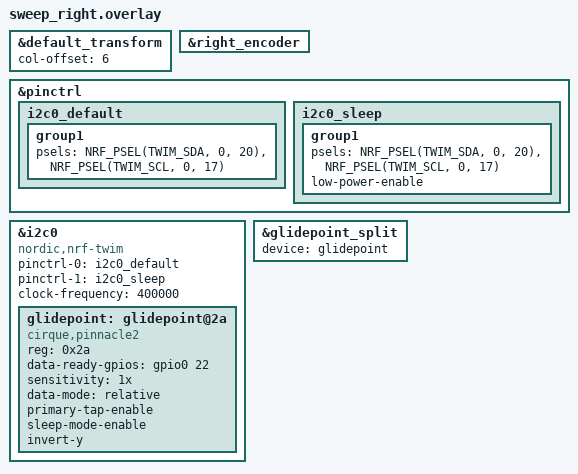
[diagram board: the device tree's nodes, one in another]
#include "sweep.dtsi"

&default_transform {
	col-offset = <6>;
};

&right_encoder {
	status = "okay";
};

&pinctrl {
	/* configuration for i2c0 device, default state */
	i2c0_default: i2c0_default {
		group1 {
			psels = <NRF_PSEL(TWIM_SDA, 0, 20)>,
			<NRF_PSEL(TWIM_SCL, 0, 17)>;
		};
	};
	
	i2c0_sleep: i2c0_sleep {
		group1 {
			psels = <NRF_PSEL(TWIM_SDA, 0, 20)>,
			<NRF_PSEL(TWIM_SCL, 0, 17)>;
			low-power-enable;
		};
	};
};

&i2c0 {
	compatible = "nordic,nrf-twim";
	status = "okay";
	
	pinctrl-0 = <&i2c0_default>;
	pinctrl-1 = <&i2c0_sleep>;
	pinctrl-names = "default", "sleep";
	
	clock-frequency = <400000>;
	
	glidepoint: glidepoint@2a{
		// Driver comes from nxtkb cirque-input-module — only "cirque,pinnacle2" is provided.
		compatible = "cirque,pinnacle2";
		reg = <0x2a>;
		status = "okay";
		data-ready-gpios = <&gpio0 22 (GPIO_ACTIVE_HIGH)>;
		// ADC attenuation: 1x = most sensitive (fastest cursor), 4x = least (slowest).
		sensitivity = "1x";
		data-mode = "relative";
		primary-tap-enable;
		sleep-mode-enable;
		invert-y;
	};
};

// "cirque,pinnacle2" is the compatible provided by the nxtkb cirque-input-module driver
&glidepoint_split {
	status = "okay";
	device = <&glidepoint>;
};
